# NANO112AN_v1 register map
File version: 1.0
Registers are 32-bit, read-write, reset 0x0 unless marked. A register's access mark holds for its fields unless they carry their own. Offsets are from the block's base; [hi:lo] are bit positions.

## CRC — PDMA Register Map
Base 0x50008E00
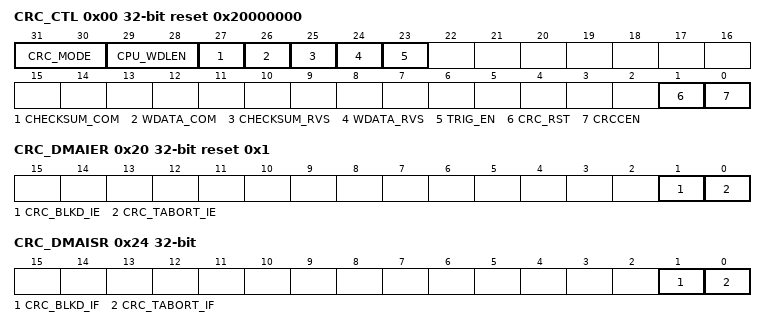
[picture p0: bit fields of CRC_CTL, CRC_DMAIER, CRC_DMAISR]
0x00 CRC_CTL reset 0x20000000 — CRC Control Register
  [31:30] CRC_MODE — CRC Polynomial Mode. This field indicates the CRC operation polynomial mode.
    0=CRC-CCITT Polynomial Mode; 1=CRC-8 Polynomial Mode; 2=CRC-16 Polynomial Mode; 3=CRC-32 Polynomial Mode
  [29:28] CPU_WDLEN — CPU Write Data Length. This field indicates the CPU write data length only when operating in CPU mode. Note1: This field is only valid when operating in CPU mode. Note2: When the write data length is 8-bit mode, the valid data in CRC_WDATA register is only CRC_WDATA [7:0] bits; if the write data length is 16-bit mode, the valid data in CRC_WDATA register is only CRC_WDATA [15:0].
    0=The write data length is 8-bit mode; 1=The write data length is 16-bit mode; 2=The write data length is 32-bit mode
  [27] CHECKSUM_COM — Checksum 1's Complement. This bit is used to enable the 1's complement function for checksum result in CRC_CHECKSUM register.
    0=1's complement for CRC checksum Disabled; 1=1's complement for CRC checksum Enabled
  [26] WDATA_COM — Write Data 1's Complement. This bit is used to enable the 1's complement function for write data value in CRC_WDTAT register.
    0=1's complement for CRC write data in Disabled; 1=1's complement for CRC write data in Enabled
  [25] CHECKSUM_RVS — Checksum Reverse. This bit is used to enable the bit order reverse function for write data value in CRC_CHECKSUM register. Note: If the checksum result is 0XDD7B0F2E, the bit order reverse for CRC checksum is 0x74F0DEBB
    0=Bit order reverse for CRC checksum Disabled; 1=Bit order reverse for CRC checksum Enabled
  [24] WDATA_RVS — Write Data Order Reverse. This bit is used to enable the bit order reverse function for write data value in CRC_WDTAT register. Note: If the write data is 0xAABBCCDD, the bit order reverse for CRC write data in is 0x55DD33BB
    0=Bit order reverse for CRC write data in Disabled; 1=Bit order reverse for CRC write data in Enabled (per byre)
  [23] TRIG_EN — Trigger Enable Control. This bit is used to trigger the CRC DMA transfer. Note1: If this bit asserts which indicates the CRC engine operation in CRC DMA mode, do not fill in any data in CRC_WDATA register. Note2: When CRC DMA transfer completed, this bit will be cleared automatically. Note3: If the bus error occurs when CRC DMA transfer data, all CRC DMA transfer will be stopped. User must reset all DMA channel before trigger DMA again.
    0=No effect; 1=CRC DMA data read or write transfer Enabled
  [1] CRC_RST — CRC Engine Reset. Note: When operated in CPU mode, setting this bit will reload the initial seed value (CRC_SEED register).
    0=No effect; 1=Reset the internal CRC state machine and internal buffer. The others contents of CRC_CTL register will not be cleared. This bit will be cleared automatically
  [0] CRCCEN — CRC Channel Enable Control
    0=No effect; 1=CRC operation Enabled
0x04 CRC_DMASAR — CRC DMA Source Address Register
  [31:0] CRC_DMASAR — CRC DMA Transfer Source Address Bits. This field indicates a 32-bit source address of CRC DMA. Note: The source address must be word alignment
0x0C CRC_DMABCR — CRC DMA Transfer Byte Count Register
  [15:0] CRC_DMABCR — CRC DMA Transfer Byte Count. This field indicates a 16-bit total transfer byte count number of CRC DMA
0x14 CRC_DMACSAR ro — CRC DMA Current Source Address Register
  [31:0] CRC_DMACSAR — CRC DMA Current Source Address Bits (Read Only). This field indicates the current source address where the CRC DMA transfer just occurs.
0x1C CRC_DMACBCR ro — CRC DMA Current Transfer Byte Count Register
  [15:0] CRC_DMACBCR — CRC DMA Current Remained Byte Count (Read Only). This field indicates the current remained byte count of CRC DMA. Note: Setting the CRC_RST bit to 1 will clear this register value.
0x20 CRC_DMAIER reset 0x1 — CRC DMA Interrupt Enable Register
  [1] CRC_BLKD_IE — CRC DMA Block Transfer Done Interrupt Enable Control. Enable this bit will generate the CRC DMA Transfer Done interrupt signal while CRC_BLKD_IF bit (CRCDMAISR [1] CRC DMA Block Transfer Done Interrupt Flag) is set to 1.
    0=Interrupt generator Disabled when CRC DMA transfer done; 1=Interrupt generator Enabled when CRC DMA transfer done
  [0] CRC_TABORT_IE — CRC DMA Read/Write Target Abort Interrupt Enable Control. Enable this bit will generate the CRC DMA Target Abort interrupt signal while CRC_TARBOT_IF bit (CRCDMAISR [0] CRC DMA Read/Write Target Abort Interrupt Flag) is set to 1.
    0=Target abort interrupt generation Disabled during CRC DMA transfer; 1=Target abort interrupt generation Enabled during CRC DMA transfer
0x24 CRC_DMAISR — CRC DMA Interrupt Status Register
  [1] CRC_BLKD_IF — CRC DMA Block Transfer Done Interrupt Flag. This bit indicates that CRC DMA transfer has finished or not. (When CRC DMA transfer done, TRIG_EN (CRC_CTL[23]) will be cleared automatically). Note: This bit is cleared by writing "1" to it.
    0=Not finished if TRIG_EN (CRC_CTL[23]) has enabled; 1=CRC transfer done if TRIG_EN (CRC_CTL[23]) has enabled
  [0] CRC_TABORT_IF — CRC DMA Read/Write Target Abort Interrupt Flag. This bit indicates that CRC bus has error or not during CRC DMA transfer. Note1: This bit is cleared by writing "1" to it. Note2: This bit indicates bus master received error response or not. If bus master received error response, it means that CRC transfer target abort is happened. DMA will stop transfer and respond this event to user then CRC state machine goes to IDLE state. When target abort occurred, user must reset DMA before transfer those data again
    0=No bus error response received during CRC DMA transfer; 1=Bus error response received during CRC DMA transfer
0x80 CRC_WDATA — CRC Write Data Register
  [31:0] CRC_WDATA — CRC Write Data Bits. When operating in CPU mode, user can write data to this field to perform CRC operation. When operating in DMA mode, this field indicates the DMA read data from memory and cannot be written. Note: When the write data length is 8-bit mode, the valid data in CRC_WDATA register is only CRC_WDATA [7:0] bits; if the write data length is 16-bit mode, the valid data in CRC_WDATA register is only CRC_WDATA [15:0].
0x84 CRC_SEED reset 0xFFFFFFFF
  [31:0] CRC_SEED — CRC Seed Value. This field indicates the CRC seed value.
0x88 CRC_CHECKSUM ro reset 0xFFFFFFFF
  [31:0] CRC_CHECKSUM — CRC Checksum Results. This fields indicates the CRC checksum result
